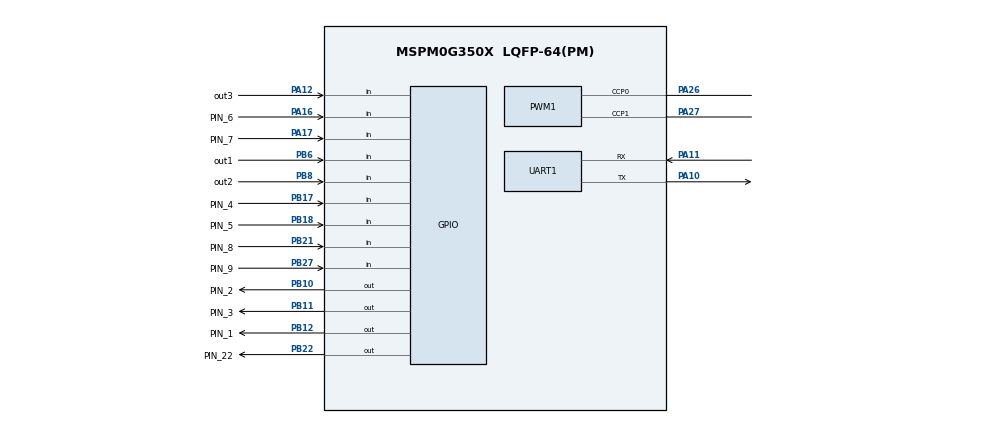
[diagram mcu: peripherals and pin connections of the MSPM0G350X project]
/**
 * @cliArgs --device "MSPM0G350X" --part "Default" --package "LQFP-64(PM)" --product "mspm0_sdk@2.05.01.01"
 * @versions {"tool":"1.24.0+4110"}
 */

/**
 * Import the modules used in this configuration.
 */
const GPIO          = scripting.addModule("/ti/driverlib/GPIO", {}, false);
const GPIO1         = GPIO.addInstance();
const GPIO2         = GPIO.addInstance();
const GPIO3         = GPIO.addInstance();
const GPIO4         = GPIO.addInstance();
const GPIO5         = GPIO.addInstance();
const GPIO6         = GPIO.addInstance();
const GPIO7         = GPIO.addInstance();
const I2C           = scripting.addModule("/ti/driverlib/I2C", {}, false);
const I2C1          = I2C.addInstance();
const PWM           = scripting.addModule("/ti/driverlib/PWM", {}, false);
const PWM1          = PWM.addInstance();
const SYSCTL        = scripting.addModule("/ti/driverlib/SYSCTL");
const TIMER         = scripting.addModule("/ti/driverlib/TIMER", {}, false);
const TIMER1        = TIMER.addInstance();
const UART          = scripting.addModule("/ti/driverlib/UART", {}, false);
const UART1         = UART.addInstance();
const ProjectConfig = scripting.addModule("/ti/project_config/ProjectConfig");

/**
 * Write custom configuration values to the imported modules.
 */
const gate7  = system.clockTree["MFCLKGATE"];
gate7.enable = true;

GPIO1.$name                          = "motorA";
GPIO1.associatedPins.create(2);
GPIO1.associatedPins[0].$name        = "PIN_0";
GPIO1.associatedPins[1].$name        = "PIN_1";
GPIO1.associatedPins[1].initialValue = "SET";
GPIO1.associatedPins[1].pin.$assign  = "PB12";

const Board = scripting.addModule("/ti/driverlib/Board", {}, false);

GPIO2.$name                          = "motorB";
GPIO2.associatedPins.create(2);
GPIO2.associatedPins[0].$name        = "PIN_2";
GPIO2.associatedPins[0].pin.$assign  = "PB10";
GPIO2.associatedPins[1].$name        = "PIN_3";
GPIO2.associatedPins[1].initialValue = "SET";
GPIO2.associatedPins[1].pin.$assign  = "PB11";

GPIO3.$name                               = "ENCODERL";
GPIO3.associatedPins.create(2);
GPIO3.associatedPins[0].$name             = "PIN_4";
GPIO3.associatedPins[0].direction         = "INPUT";
GPIO3.associatedPins[0].ioStructure       = "SD";
GPIO3.associatedPins[0].interruptEn       = true;
GPIO3.associatedPins[0].polarity          = "RISE";
GPIO3.associatedPins[0].interruptPriority = "0";
GPIO3.associatedPins[0].pin.$assign       = "PB17";
GPIO3.associatedPins[1].$name             = "PIN_5";
GPIO3.associatedPins[1].direction         = "INPUT";
GPIO3.associatedPins[1].ioStructure       = "SD";
GPIO3.associatedPins[1].pin.$assign       = "PB18";

GPIO4.$name                         = "LED1";
GPIO4.port                          = "PORTB";
GPIO4.associatedPins[0].$name       = "PIN_22";
GPIO4.associatedPins[0].pin.$assign = "PB22";

GPIO5.$name                               = "ENCODERR";
GPIO5.associatedPins.create(2);
GPIO5.associatedPins[0].$name             = "PIN_6";
GPIO5.associatedPins[0].direction         = "INPUT";
GPIO5.associatedPins[0].interruptEn       = true;
GPIO5.associatedPins[0].polarity          = "RISE";
GPIO5.associatedPins[0].interruptPriority = "0";
GPIO5.associatedPins[0].pin.$assign       = "PA16";
GPIO5.associatedPins[1].$name             = "PIN_7";
GPIO5.associatedPins[1].direction         = "INPUT";
GPIO5.associatedPins[1].pin.$assign       = "PA17";

GPIO6.$name                          = "Trace";
GPIO6.associatedPins.create(5);
GPIO6.associatedPins[0].$name        = "out1";
GPIO6.associatedPins[0].direction    = "INPUT";
GPIO6.associatedPins[0].assignedPin  = "6";
GPIO6.associatedPins[0].pin.$assign  = "PB6";
GPIO6.associatedPins[1].$name        = "out2";
GPIO6.associatedPins[1].direction    = "INPUT";
GPIO6.associatedPins[1].assignedPort = "PORTB";
GPIO6.associatedPins[1].assignedPin  = "8";
GPIO6.associatedPins[1].pin.$assign  = "PB8";
GPIO6.associatedPins[2].$name        = "out3";
GPIO6.associatedPins[2].direction    = "INPUT";
GPIO6.associatedPins[2].assignedPin  = "12";
GPIO6.associatedPins[2].assignedPort = "PORTA";
GPIO6.associatedPins[2].pin.$assign  = "PA12";
GPIO6.associatedPins[3].$name        = "out4";
GPIO6.associatedPins[3].direction    = "INPUT";
GPIO6.associatedPins[3].assignedPort = "PORTB";
GPIO6.associatedPins[3].assignedPin  = "5";
GPIO6.associatedPins[4].$name        = "out5";
GPIO6.associatedPins[4].direction    = "INPUT";
GPIO6.associatedPins[4].assignedPort = "PORTA";
GPIO6.associatedPins[4].assignedPin  = "9";

GPIO7.$name                              = "KEY";
GPIO7.port                               = "PORTB";
GPIO7.portSegment                        = "Upper";
GPIO7.associatedPins.create(2);
GPIO7.associatedPins[0].$name            = "PIN_8";
GPIO7.associatedPins[0].direction        = "INPUT";
GPIO7.associatedPins[0].internalResistor = "PULL_UP";
GPIO7.associatedPins[0].pin.$assign      = "PB21";
GPIO7.associatedPins[1].$name            = "PIN_9";
GPIO7.associatedPins[1].direction        = "INPUT";
GPIO7.associatedPins[1].internalResistor = "PULL_UP";
GPIO7.associatedPins[1].pin.$assign      = "PB27";

I2C1.$name                           = "I2C_0";
I2C1.basicEnableController           = true;
I2C1.basicControllerStandardBusSpeed = "Fast";
I2C1.peripheral.$assign              = "I2C0";
I2C1.sdaPinConfig.$name              = "ti_driverlib_gpio_GPIOPinGeneric0";
I2C1.sclPinConfig.$name              = "ti_driverlib_gpio_GPIOPinGeneric1";

PWM1.$name                              = "PWM_MOTOR";
PWM1.timerStartTimer                    = true;
PWM1.pwmMode                            = "EDGE_ALIGN_UP";
PWM1.clockDivider                       = 8;
PWM1.peripheral.$assign                 = "TIMG8";
PWM1.peripheral.ccp0Pin.$assign         = "PA26";
PWM1.peripheral.ccp1Pin.$assign         = "PA27";
PWM1.PWM_CHANNEL_0.$name                = "ti_driverlib_pwm_PWMTimerCC0";
PWM1.PWM_CHANNEL_0.dutyCycle            = 50;
PWM1.PWM_CHANNEL_1.$name                = "ti_driverlib_pwm_PWMTimerCC1";
PWM1.PWM_CHANNEL_1.dutyCycle            = 100;
PWM1.ccp0PinConfig.direction            = scripting.forceWrite("OUTPUT");
PWM1.ccp0PinConfig.hideOutputInversion  = scripting.forceWrite(false);
PWM1.ccp0PinConfig.onlyInternalResistor = scripting.forceWrite(false);
PWM1.ccp0PinConfig.passedPeripheralType = scripting.forceWrite("Digital");
PWM1.ccp0PinConfig.$name                = "ti_driverlib_gpio_GPIOPinGeneric4";
PWM1.ccp1PinConfig.direction            = scripting.forceWrite("OUTPUT");
PWM1.ccp1PinConfig.hideOutputInversion  = scripting.forceWrite(false);
PWM1.ccp1PinConfig.onlyInternalResistor = scripting.forceWrite(false);
PWM1.ccp1PinConfig.passedPeripheralType = scripting.forceWrite("Digital");
PWM1.ccp1PinConfig.$name                = "ti_driverlib_gpio_GPIOPinGeneric5";

SYSCTL.clockTreeEn = true;

TIMER1.$name              = "TIMER_0";
TIMER1.timerClkPrescale   = 100;
TIMER1.timerStartTimer    = true;
TIMER1.interrupts         = ["ZERO"];
TIMER1.timerMode          = "PERIODIC";
TIMER1.timerClkDiv        = 8;
TIMER1.interruptPriority  = "0";
TIMER1.timerPeriod        = "30 ms";
TIMER1.peripheral.$assign = "TIMG0";

UART1.$name                    = "UART_0";
UART1.uartClkSrc               = "MFCLK";
UART1.enableDMATX              = false;
UART1.enabledInterrupts        = ["RX"];
UART1.peripheral.rxPin.$assign = "PA11";
UART1.peripheral.txPin.$assign = "PA10";
UART1.txPinConfig.$name        = "ti_driverlib_gpio_GPIOPinGeneric2";
UART1.rxPinConfig.$name        = "ti_driverlib_gpio_GPIOPinGeneric3";

/**
 * Pinmux solution for unlocked pins/peripherals. This ensures that minor changes to the automatic solver in a future
 * version of the tool will not impact the pinmux you originally saw.  These lines can be completely deleted in order to
 * re-solve from scratch.
 */
GPIO1.associatedPins[0].pin.$suggestSolution = "PB13";
Board.peripheral.$suggestSolution            = "DEBUGSS";
Board.peripheral.swclkPin.$suggestSolution   = "PA20";
Board.peripheral.swdioPin.$suggestSolution   = "PA19";
GPIO6.associatedPins[3].pin.$suggestSolution = "PB5";
GPIO6.associatedPins[4].pin.$suggestSolution = "PA9";
I2C1.peripheral.sdaPin.$suggestSolution      = "PA0";
I2C1.peripheral.sclPin.$suggestSolution      = "PA1";
UART1.peripheral.$suggestSolution            = "UART0";
